AUTOSAR XML (schema 321)
package /ComponentType
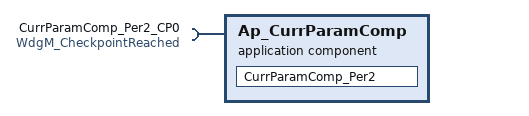
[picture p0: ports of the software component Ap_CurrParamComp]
  application software component type Ap_CurrParamComp
    require port CurrParamComp_Per2_CP0: client-com-spec=CheckpointReached, required-interface=WdgM_CheckpointReached
  internal behavior Ap_CurrParamComp_InternalBehavior: component=Ap_CurrParamComp, port-api-option{enable-take-address=false, indirect-api=false, port=CurrParamComp_Per2_CP0}
    runnable CurrParamComp_Per2
      sync call SC_CurrParamComp_Per2_CP0_CheckpointReached: operation=CurrParamComp_Per2_CP0.CheckpointReached, timeout=0
  swc implementation Ap_CurrParamComp_Implementation: behavior=Ap_CurrParamComp_InternalBehavior
    code-descriptors:
      code Code: type=SRC
package /PortInterface
  client server interface WdgM_CheckpointReached: is-service=true
    operation CheckpointReached: possible-error=E_NOT_OK  # Indicates to the Watchdog Manager that a Checkpoint within a Supervised Entity has been reached.
    error E_NOT_OK: error-code=1
